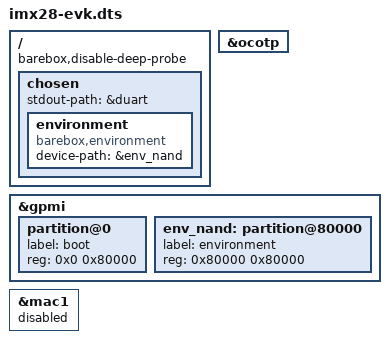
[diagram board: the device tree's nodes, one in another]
#include <arm/nxp/mxs/imx28-evk.dts>

/ {
	barebox,disable-deep-probe;

	chosen {
		stdout-path = &duart;

		environment {
			compatible = "barebox,environment";
			device-path = &env_nand;
		};
	};
};

&ocotp {
	status = "okay";
};

&gpmi {
	partition@0 {
		label = "boot";
		reg = <0x0 0x80000>;
	};

	env_nand: partition@80000 {
		label = "environment";
		reg = <0x80000 0x80000>;
	};
};

&mac1 {
	status = "disabled";
};
